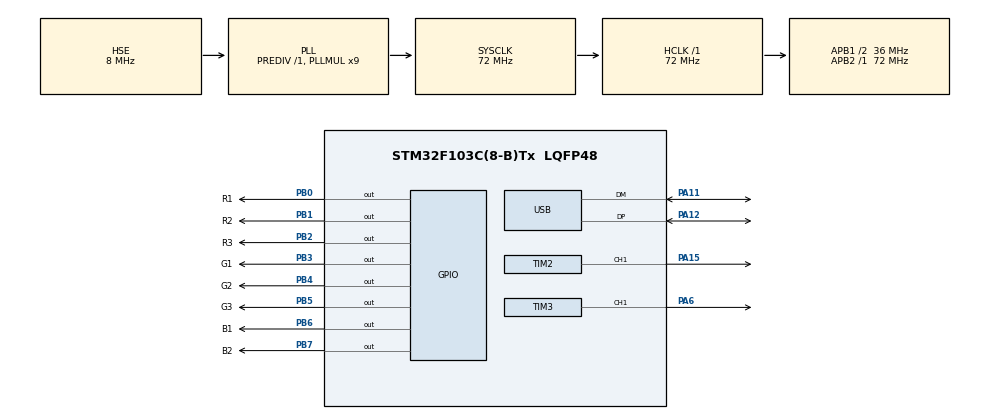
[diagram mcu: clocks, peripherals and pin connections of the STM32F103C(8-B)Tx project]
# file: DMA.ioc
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Dma.Request0=TIM1_UP
Dma.TIM1_UP.0.Direction=DMA_MEMORY_TO_PERIPH
Dma.TIM1_UP.0.Instance=DMA1_Channel5
Dma.TIM1_UP.0.MemDataAlignment=DMA_MDATAALIGN_BYTE
Dma.TIM1_UP.0.MemInc=DMA_MINC_ENABLE
Dma.TIM1_UP.0.Mode=DMA_NORMAL
Dma.TIM1_UP.0.PeriphDataAlignment=DMA_PDATAALIGN_BYTE
Dma.TIM1_UP.0.PeriphInc=DMA_PINC_DISABLE
Dma.TIM1_UP.0.Priority=DMA_PRIORITY_VERY_HIGH
Mcu.Family=STM32F1
Mcu.Name=STM32F103C(8-B)Tx
Mcu.Package=LQFP48
NVIC.DMA1_Channel5_IRQn=true\:0\:0\:true\:false\:true\:false\:true\:true
NVIC.PriorityGroup=NVIC_PRIORITYGROUP_4
NVIC.TIM2_IRQn=true\:1\:0\:true\:false\:true\:true\:true\:true
NVIC.TIM3_IRQn=true\:0\:0\:false\:false\:true\:true\:true\:true
NVIC.USB_LP_CAN1_RX0_IRQn=true\:2\:0\:true\:false\:true\:false\:true\:true
PA11.Mode=Device
PA11.Signal=USB_DM
PA12.Mode=Device
PA12.Signal=USB_DP
PA13.Mode=Serial_Wire
PA13.Signal=SYS_JTMS-SWDIO
PA14.Mode=Serial_Wire
PA14.Signal=SYS_JTCK-SWCLK
PA15.Signal=S_TIM2_CH1_ETR
PA6.Signal=S_TIM3_CH1
PB0.GPIO_Label=R1
PB0.GPIO_Speed=GPIO_SPEED_FREQ_HIGH
PB0.Signal=GPIO_Output
PB1.GPIO_Label=R2
PB1.GPIO_Speed=GPIO_SPEED_FREQ_HIGH
PB1.Signal=GPIO_Output
PB2.GPIO_Label=R3
PB2.GPIO_Speed=GPIO_SPEED_FREQ_HIGH
PB2.Signal=GPIO_Output
PB3.GPIO_Label=G1
PB3.GPIO_Speed=GPIO_SPEED_FREQ_HIGH
PB3.Signal=GPIO_Output
PB4.GPIO_Label=G2
PB4.GPIO_Speed=GPIO_SPEED_FREQ_HIGH
PB4.Signal=GPIO_Output
PB5.GPIO_Label=G3
PB5.GPIO_Speed=GPIO_SPEED_FREQ_HIGH
PB5.Signal=GPIO_Output
PB6.GPIO_Label=B1
PB6.GPIO_Speed=GPIO_SPEED_FREQ_HIGH
PB6.Signal=GPIO_Output
PB7.GPIO_Label=B2
PB7.GPIO_Speed=GPIO_SPEED_FREQ_HIGH
PB7.Signal=GPIO_Output
PD0-OSC_IN.Mode=HSE-External-Oscillator
PD0-OSC_IN.Signal=RCC_OSC_IN
PD1-OSC_OUT.Mode=HSE-External-Oscillator
PD1-OSC_OUT.Signal=RCC_OSC_OUT
ProjectManager.HeapSize=0x200
ProjectManager.StackSize=0x400
ProjectManager.TargetToolchain=STM32CubeIDE
RCC.AHBFreq_Value=72000000
RCC.APB1CLKDivider=RCC_HCLK_DIV2
RCC.APB1Freq_Value=36000000
RCC.APB1TimFreq_Value=72000000
RCC.APB2Freq_Value=72000000
RCC.APB2TimFreq_Value=72000000
RCC.HCLKFreq_Value=72000000
RCC.PLLMUL=RCC_PLL_MUL9
RCC.PLLSourceVirtual=RCC_PLLSOURCE_HSE
RCC.SYSCLKFreq_VALUE=72000000
RCC.SYSCLKSource=RCC_SYSCLKSOURCE_PLLCLK
RCC.USBFreq_Value=48000000
RCC.USBPrescaler=RCC_USBCLKSOURCE_PLL_DIV1_5
SH.S_TIM2_CH1_ETR.0=TIM2_CH1,PWM Generation1 CH1
SH.S_TIM3_CH1.0=TIM3_CH1,PWM Generation1 CH1
TIM1.Period=12-1
TIM1.Prescaler=0
TIM1.TIM_MasterOutputTrigger=TIM_TRGO_UPDATE
TIM2.Channel-PWM\ Generation1\ CH1=TIM_CHANNEL_1
TIM2.OCPolarity_1=TIM_OCPOLARITY_LOW
TIM2.Period=800-1
TIM2.Prescaler=3-1
TIM2.Pulse-PWM\ Generation1\ CH1=96
TIM2.TIM_MasterOutputTrigger=TIM_TRGO_UPDATE
TIM3.Channel-PWM\ Generation1\ CH1=TIM_CHANNEL_1
TIM3.OCPolarity_1=TIM_OCPOLARITY_LOW
TIM3.Period=524
TIM3.Prescaler=0
TIM3.Pulse-PWM\ Generation1\ CH1=2
TIM3.TIM_MasterOutputTrigger=TIM_TRGO_UPDATE
USB_DEVICE.CLASS_NAME_FS=CDC
USB_DEVICE.VirtualMode=Cdc
USB_DEVICE.VirtualModeFS=Cdc_FS
VP_TIM1_VS_ClockSourceINT.Mode=Internal
VP_TIM3_VS_ClockSourceITR.Mode=TriggerSource_ITR1
VP_TIM3_VS_ControllerModeClock.Mode=Clock Mode
VP_USB_DEVICE_VS_USB_DEVICE_CDC_FS.Mode=CDC_FS
board=custom

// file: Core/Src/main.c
/* USER CODE BEGIN Header */
/**
  ******************************************************************************
  * @file           : main.c
  * @brief          : Main program body
  ******************************************************************************
  * @attention
  *
  * Copyright (c) 2025 STMicroelectronics.
  * All rights reserved.
  *
  * This software is licensed under terms that can be found in the LICENSE file
  * in the root directory of this software component.
  * If no LICENSE file comes with this software, it is provided AS-IS.
  *
  ******************************************************************************
  */
/* USER CODE END Header */
#include "main.h"
#include "usb_device.h"

/* USER CODE BEGIN Includes */

extern void VGA_Init();
/* USER CODE END Includes */

TIM_HandleTypeDef htim1;
TIM_HandleTypeDef htim2;
TIM_HandleTypeDef htim3;
DMA_HandleTypeDef hdma_tim1_up;

void SystemClock_Config(void);
static void MX_GPIO_Init(void);
static void MX_DMA_Init(void);
static void MX_TIM1_Init(void);
static void MX_TIM2_Init(void);
static void MX_TIM3_Init(void);

int main(void)
{

  /* MCU Configuration--------------------------------------------------------*/

  /* Reset of all peripherals, Initializes the Flash interface and the Systick. */
  HAL_Init();

  /* Configure the system clock */
  SystemClock_Config();

  /* Initialize all configured peripherals */
  MX_GPIO_Init();
  MX_DMA_Init();
  MX_TIM1_Init();
  MX_TIM2_Init();
  MX_TIM3_Init();
  MX_USB_DEVICE_Init();
  /* USER CODE BEGIN 2 */

  HAL_TIM_Base_Start(&htim1);
  HAL_TIM_Base_Start_IT(&htim2);
  HAL_TIM_Base_Start_IT(&htim3);

  HAL_TIM_PWM_Start(&htim2, TIM_CHANNEL_1);
  HAL_TIM_PWM_Start(&htim3, TIM_CHANNEL_1);

    VGA_Init();

  /* USER CODE END 2 */

  /* Infinite loop */
  /* USER CODE BEGIN WHILE */
  while (1)
  {
	  USBTest_Function();

    /* USER CODE END WHILE */

  }
}

void SystemClock_Config(void)
{
  RCC_OscInitTypeDef RCC_OscInitStruct = {0};
  RCC_ClkInitTypeDef RCC_ClkInitStruct = {0};
  RCC_PeriphCLKInitTypeDef PeriphClkInit = {0};

  /** Initializes the RCC Oscillators according to the specified parameters
  * in the RCC_OscInitTypeDef structure.
  */
  RCC_OscInitStruct.OscillatorType = RCC_OSCILLATORTYPE_HSE;
  RCC_OscInitStruct.HSEState = RCC_HSE_ON;
  RCC_OscInitStruct.HSEPredivValue = RCC_HSE_PREDIV_DIV1;
  RCC_OscInitStruct.HSIState = RCC_HSI_ON;
  RCC_OscInitStruct.PLL.PLLState = RCC_PLL_ON;
  RCC_OscInitStruct.PLL.PLLSource = RCC_PLLSOURCE_HSE;
  RCC_OscInitStruct.PLL.PLLMUL = RCC_PLL_MUL9;
  if (HAL_RCC_OscConfig(&RCC_OscInitStruct) != HAL_OK)
  {
    Error_Handler();
  }

  /** Initializes the CPU, AHB and APB buses clocks
  */
  RCC_ClkInitStruct.ClockType = RCC_CLOCKTYPE_HCLK|RCC_CLOCKTYPE_SYSCLK
                              |RCC_CLOCKTYPE_PCLK1|RCC_CLOCKTYPE_PCLK2;
  RCC_ClkInitStruct.SYSCLKSource = RCC_SYSCLKSOURCE_PLLCLK;
  RCC_ClkInitStruct.AHBCLKDivider = RCC_SYSCLK_DIV1;
  RCC_ClkInitStruct.APB1CLKDivider = RCC_HCLK_DIV2;
  RCC_ClkInitStruct.APB2CLKDivider = RCC_HCLK_DIV1;

  if (HAL_RCC_ClockConfig(&RCC_ClkInitStruct, FLASH_LATENCY_2) != HAL_OK)
  {
    Error_Handler();
  }
  PeriphClkInit.PeriphClockSelection = RCC_PERIPHCLK_USB;
  PeriphClkInit.UsbClockSelection = RCC_USBCLKSOURCE_PLL_DIV1_5;
  if (HAL_RCCEx_PeriphCLKConfig(&PeriphClkInit) != HAL_OK)
  {
    Error_Handler();
  }
}

static void MX_TIM1_Init(void)
{

  TIM_ClockConfigTypeDef sClockSourceConfig = {0};
  TIM_MasterConfigTypeDef sMasterConfig = {0};

  htim1.Instance = TIM1;
  htim1.Init.Prescaler = 0;
  htim1.Init.CounterMode = TIM_COUNTERMODE_UP;
  htim1.Init.Period = 12-1;
  htim1.Init.ClockDivision = TIM_CLOCKDIVISION_DIV1;
  htim1.Init.RepetitionCounter = 0;
  htim1.Init.AutoReloadPreload = TIM_AUTORELOAD_PRELOAD_DISABLE;
  if (HAL_TIM_Base_Init(&htim1) != HAL_OK)
  {
    Error_Handler();
  }
  sClockSourceConfig.ClockSource = TIM_CLOCKSOURCE_INTERNAL;
  if (HAL_TIM_ConfigClockSource(&htim1, &sClockSourceConfig) != HAL_OK)
  {
    Error_Handler();
  }
  sMasterConfig.MasterOutputTrigger = TIM_TRGO_UPDATE;
  sMasterConfig.MasterSlaveMode = TIM_MASTERSLAVEMODE_DISABLE;
  if (HAL_TIMEx_MasterConfigSynchronization(&htim1, &sMasterConfig) != HAL_OK)
  {
    Error_Handler();
  }

}

static void MX_TIM2_Init(void)
{

  TIM_MasterConfigTypeDef sMasterConfig = {0};
  TIM_OC_InitTypeDef sConfigOC = {0};

  htim2.Instance = TIM2;
  htim2.Init.Prescaler = 3-1;
  htim2.Init.CounterMode = TIM_COUNTERMODE_UP;
  htim2.Init.Period = 800-1;
  htim2.Init.ClockDivision = TIM_CLOCKDIVISION_DIV1;
  htim2.Init.AutoReloadPreload = TIM_AUTORELOAD_PRELOAD_DISABLE;
  if (HAL_TIM_PWM_Init(&htim2) != HAL_OK)
  {
    Error_Handler();
  }
  sMasterConfig.MasterOutputTrigger = TIM_TRGO_UPDATE;
  sMasterConfig.MasterSlaveMode = TIM_MASTERSLAVEMODE_DISABLE;
  if (HAL_TIMEx_MasterConfigSynchronization(&htim2, &sMasterConfig) != HAL_OK)
  {
    Error_Handler();
  }
  sConfigOC.OCMode = TIM_OCMODE_PWM1;
  sConfigOC.Pulse = 96;
  sConfigOC.OCPolarity = TIM_OCPOLARITY_LOW;
  sConfigOC.OCFastMode = TIM_OCFAST_DISABLE;
  if (HAL_TIM_PWM_ConfigChannel(&htim2, &sConfigOC, TIM_CHANNEL_1) != HAL_OK)
  {
    Error_Handler();
  }
  HAL_TIM_MspPostInit(&htim2);

}

static void MX_TIM3_Init(void)
{

  TIM_SlaveConfigTypeDef sSlaveConfig = {0};
  TIM_MasterConfigTypeDef sMasterConfig = {0};
  TIM_OC_InitTypeDef sConfigOC = {0};

  htim3.Instance = TIM3;
  htim3.Init.Prescaler = 0;
  htim3.Init.CounterMode = TIM_COUNTERMODE_UP;
  htim3.Init.Period = 524;
  htim3.Init.ClockDivision = TIM_CLOCKDIVISION_DIV1;
  htim3.Init.AutoReloadPreload = TIM_AUTORELOAD_PRELOAD_DISABLE;
  if (HAL_TIM_Base_Init(&htim3) != HAL_OK)
  {
    Error_Handler();
  }
  if (HAL_TIM_PWM_Init(&htim3) != HAL_OK)
  {
    Error_Handler();
  }
  sSlaveConfig.SlaveMode = TIM_SLAVEMODE_EXTERNAL1;
  sSlaveConfig.InputTrigger = TIM_TS_ITR1;
  if (HAL_TIM_SlaveConfigSynchro(&htim3, &sSlaveConfig) != HAL_OK)
  {
    Error_Handler();
  }
  sMasterConfig.MasterOutputTrigger = TIM_TRGO_UPDATE;
  sMasterConfig.MasterSlaveMode = TIM_MASTERSLAVEMODE_DISABLE;
  if (HAL_TIMEx_MasterConfigSynchronization(&htim3, &sMasterConfig) != HAL_OK)
  {
    Error_Handler();
  }
  sConfigOC.OCMode = TIM_OCMODE_PWM1;
  sConfigOC.Pulse = 2;
  sConfigOC.OCPolarity = TIM_OCPOLARITY_LOW;
  sConfigOC.OCFastMode = TIM_OCFAST_DISABLE;
  if (HAL_TIM_PWM_ConfigChannel(&htim3, &sConfigOC, TIM_CHANNEL_1) != HAL_OK)
  {
    Error_Handler();
  }
  HAL_TIM_MspPostInit(&htim3);

}

static void MX_DMA_Init(void)
{

  /* DMA controller clock enable */
  __HAL_RCC_DMA1_CLK_ENABLE();

  /* DMA interrupt init */
  /* DMA1_Channel5_IRQn interrupt configuration */
  HAL_NVIC_SetPriority(DMA1_Channel5_IRQn, 0, 0);
  HAL_NVIC_EnableIRQ(DMA1_Channel5_IRQn);

}

static void MX_GPIO_Init(void)
{
  GPIO_InitTypeDef GPIO_InitStruct = {0};

  /* GPIO Ports Clock Enable */
  __HAL_RCC_GPIOD_CLK_ENABLE();
  __HAL_RCC_GPIOA_CLK_ENABLE();
  __HAL_RCC_GPIOB_CLK_ENABLE();

  /*Configure GPIO pin Output Level */
  HAL_GPIO_WritePin(GPIOB, R1_Pin|R2_Pin|R3_Pin|G1_Pin
                          |G2_Pin|G3_Pin|B1_Pin|B2_Pin, GPIO_PIN_RESET);

  /*Configure GPIO pins : R1_Pin R2_Pin R3_Pin G1_Pin
                           G2_Pin G3_Pin B1_Pin B2_Pin */
  GPIO_InitStruct.Pin = R1_Pin|R2_Pin|R3_Pin|G1_Pin
                          |G2_Pin|G3_Pin|B1_Pin|B2_Pin;
  GPIO_InitStruct.Mode = GPIO_MODE_OUTPUT_PP;
  GPIO_InitStruct.Pull = GPIO_NOPULL;
  GPIO_InitStruct.Speed = GPIO_SPEED_FREQ_HIGH;
  HAL_GPIO_Init(GPIOB, &GPIO_InitStruct);

}

void Error_Handler(void)
{
  __disable_irq();
  while (1)
  {
  }
}
